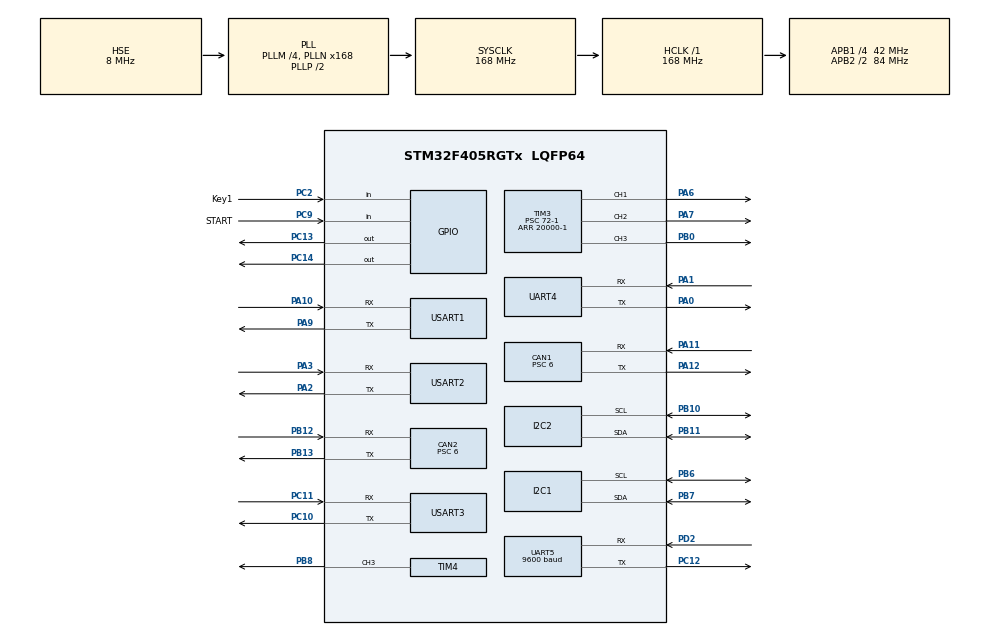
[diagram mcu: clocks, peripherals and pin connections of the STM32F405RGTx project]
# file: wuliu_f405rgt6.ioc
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CAN1.ABOM=ENABLE
CAN1.BS1=CAN_BS1_11TQ
CAN1.BS2=CAN_BS2_2TQ
CAN1.CalculateBaudRate=500000
CAN1.CalculateTimeBit=2000
CAN1.CalculateTimeQuantum=142.85714285714286
CAN1.NART=ENABLE
CAN1.Prescaler=6
CAN2.BS1=CAN_BS1_11TQ
CAN2.BS2=CAN_BS2_2TQ
CAN2.CalculateBaudRate=500000
CAN2.CalculateTimeBit=2000
CAN2.CalculateTimeQuantum=142.85714285714286
CAN2.Prescaler=6
Dma.Request0=USART1_RX
Dma.Request1=USART1_TX
Dma.Request2=USART2_RX
Dma.Request3=USART2_TX
Dma.Request4=UART4_RX
Dma.Request5=UART4_TX
Dma.Request6=USART3_RX
Dma.Request7=USART3_TX
Dma.UART4_RX.4.Direction=DMA_PERIPH_TO_MEMORY
Dma.UART4_RX.4.FIFOMode=DMA_FIFOMODE_DISABLE
Dma.UART4_RX.4.Instance=DMA1_Stream2
Dma.UART4_RX.4.MemDataAlignment=DMA_MDATAALIGN_BYTE
Dma.UART4_RX.4.MemInc=DMA_MINC_ENABLE
Dma.UART4_RX.4.Mode=DMA_CIRCULAR
Dma.UART4_RX.4.PeriphDataAlignment=DMA_PDATAALIGN_BYTE
Dma.UART4_RX.4.PeriphInc=DMA_PINC_DISABLE
Dma.UART4_RX.4.Priority=DMA_PRIORITY_LOW
Dma.UART4_TX.5.Direction=DMA_MEMORY_TO_PERIPH
Dma.UART4_TX.5.FIFOMode=DMA_FIFOMODE_DISABLE
Dma.UART4_TX.5.Instance=DMA1_Stream4
Dma.UART4_TX.5.MemDataAlignment=DMA_MDATAALIGN_BYTE
Dma.UART4_TX.5.MemInc=DMA_MINC_ENABLE
Dma.UART4_TX.5.Mode=DMA_NORMAL
Dma.UART4_TX.5.PeriphDataAlignment=DMA_PDATAALIGN_BYTE
Dma.UART4_TX.5.PeriphInc=DMA_PINC_DISABLE
Dma.UART4_TX.5.Priority=DMA_PRIORITY_LOW
Dma.USART1_RX.0.Direction=DMA_PERIPH_TO_MEMORY
Dma.USART1_RX.0.FIFOMode=DMA_FIFOMODE_DISABLE
Dma.USART1_RX.0.Instance=DMA2_Stream2
Dma.USART1_RX.0.MemDataAlignment=DMA_MDATAALIGN_BYTE
Dma.USART1_RX.0.MemInc=DMA_MINC_ENABLE
Dma.USART1_RX.0.Mode=DMA_NORMAL
Dma.USART1_RX.0.PeriphDataAlignment=DMA_PDATAALIGN_BYTE
Dma.USART1_RX.0.PeriphInc=DMA_PINC_DISABLE
Dma.USART1_RX.0.Priority=DMA_PRIORITY_LOW
Dma.USART1_TX.1.Direction=DMA_MEMORY_TO_PERIPH
Dma.USART1_TX.1.FIFOMode=DMA_FIFOMODE_DISABLE
Dma.USART1_TX.1.Instance=DMA2_Stream7
Dma.USART1_TX.1.MemDataAlignment=DMA_MDATAALIGN_BYTE
Dma.USART1_TX.1.MemInc=DMA_MINC_ENABLE
Dma.USART1_TX.1.Mode=DMA_NORMAL
Dma.USART1_TX.1.PeriphDataAlignment=DMA_PDATAALIGN_BYTE
Dma.USART1_TX.1.PeriphInc=DMA_PINC_DISABLE
Dma.USART1_TX.1.Priority=DMA_PRIORITY_LOW
Dma.USART2_RX.2.Direction=DMA_PERIPH_TO_MEMORY
Dma.USART2_RX.2.FIFOMode=DMA_FIFOMODE_DISABLE
Dma.USART2_RX.2.Instance=DMA1_Stream5
Dma.USART2_RX.2.MemDataAlignment=DMA_MDATAALIGN_BYTE
Dma.USART2_RX.2.MemInc=DMA_MINC_ENABLE
Dma.USART2_RX.2.Mode=DMA_CIRCULAR
Dma.USART2_RX.2.PeriphDataAlignment=DMA_PDATAALIGN_BYTE
Dma.USART2_RX.2.PeriphInc=DMA_PINC_DISABLE
Dma.USART2_RX.2.Priority=DMA_PRIORITY_LOW
Dma.USART2_TX.3.Direction=DMA_MEMORY_TO_PERIPH
Dma.USART2_TX.3.FIFOMode=DMA_FIFOMODE_DISABLE
Dma.USART2_TX.3.Instance=DMA1_Stream6
Dma.USART2_TX.3.MemDataAlignment=DMA_MDATAALIGN_BYTE
Dma.USART2_TX.3.MemInc=DMA_MINC_ENABLE
Dma.USART2_TX.3.Mode=DMA_NORMAL
Dma.USART2_TX.3.PeriphDataAlignment=DMA_PDATAALIGN_BYTE
Dma.USART2_TX.3.PeriphInc=DMA_PINC_DISABLE
Dma.USART2_TX.3.Priority=DMA_PRIORITY_LOW
Dma.USART3_RX.6.Direction=DMA_PERIPH_TO_MEMORY
Dma.USART3_RX.6.FIFOMode=DMA_FIFOMODE_DISABLE
Dma.USART3_RX.6.Instance=DMA1_Stream1
Dma.USART3_RX.6.MemDataAlignment=DMA_MDATAALIGN_BYTE
Dma.USART3_RX.6.MemInc=DMA_MINC_ENABLE
Dma.USART3_RX.6.Mode=DMA_NORMAL
Dma.USART3_RX.6.PeriphDataAlignment=DMA_PDATAALIGN_BYTE
Dma.USART3_RX.6.PeriphInc=DMA_PINC_DISABLE
Dma.USART3_RX.6.Priority=DMA_PRIORITY_LOW
Dma.USART3_TX.7.Direction=DMA_MEMORY_TO_PERIPH
Dma.USART3_TX.7.FIFOMode=DMA_FIFOMODE_DISABLE
Dma.USART3_TX.7.Instance=DMA1_Stream3
Dma.USART3_TX.7.MemDataAlignment=DMA_MDATAALIGN_BYTE
Dma.USART3_TX.7.MemInc=DMA_MINC_ENABLE
Dma.USART3_TX.7.Mode=DMA_NORMAL
Dma.USART3_TX.7.PeriphDataAlignment=DMA_PDATAALIGN_BYTE
Dma.USART3_TX.7.PeriphInc=DMA_PINC_DISABLE
Dma.USART3_TX.7.Priority=DMA_PRIORITY_LOW
FREERTOS.Queues01=KeyQueue,16,uint8_t,0,Dynamic,NULL,NULL;maxicamQueue,16,34,1,Dynamic,NULL,NULL
FREERTOS.Tasks01=defaultTask,8,512,StartDefaultTask,Default,NULL,Dynamic,NULL,NULL;CHASSIS_TASK,25,128,chassis_task,As external,NULL,Dynamic,NULL,NULL;POSITION_TASK,24,128,position_task,As external,NULL,Dynamic,NULL,NULL;MAIN_TASK,16,256,main_task,As external,NULL,Dynamic,NULL,NULL;UART_RX_TASK,18,128,uart_rx_task,As external,NULL,Dynamic,NULL,NULL;MUSIC_TASK,10,128,music_task,As external,NULL,Dynamic,NULL,NULL;KEY_TASK,17,128,key_task,As external,NULL,Dynamic,NULL,NULL;OUTPUT_TASK,11,1024,output_task,As external,NULL,Dynamic,NULL,NULL;RADAR_TASK,19,2048,radar_task,As external,NULL,Dynamic,NULL,NULL;TEST_RADAR_TASK,8,128,test_radar_task,As external,NULL,Dynamic,NULL,NULL
FREERTOS.configTOTAL_HEAP_SIZE=24576
I2C1.I2C_Mode=I2C_Fast
I2C2.I2C_Mode=I2C_Fast
Mcu.Family=STM32F4
Mcu.Name=STM32F405RGTx
Mcu.Package=LQFP64
NVIC.CAN1_RX0_IRQn=true\:5\:0\:false\:false\:true\:true\:true\:true\:true
NVIC.CAN2_RX0_IRQn=true\:5\:0\:false\:false\:true\:true\:true\:true\:true
NVIC.DMA1_Stream1_IRQn=true\:5\:0\:false\:false\:true\:true\:false\:true\:true
NVIC.DMA1_Stream2_IRQn=true\:5\:0\:false\:false\:true\:true\:false\:true\:true
NVIC.DMA1_Stream3_IRQn=true\:5\:0\:false\:false\:true\:true\:false\:true\:true
NVIC.DMA1_Stream4_IRQn=true\:5\:0\:false\:false\:true\:true\:false\:true\:true
NVIC.DMA1_Stream5_IRQn=true\:5\:0\:false\:false\:true\:true\:false\:true\:true
NVIC.DMA1_Stream6_IRQn=true\:5\:0\:false\:false\:true\:true\:false\:true\:true
NVIC.DMA2_Stream2_IRQn=true\:5\:0\:false\:false\:true\:true\:false\:true\:true
NVIC.DMA2_Stream7_IRQn=true\:5\:0\:false\:false\:true\:true\:false\:true\:true
NVIC.PriorityGroup=NVIC_PRIORITYGROUP_4
NVIC.TIM6_DAC_IRQn=true\:15\:0\:false\:false\:true\:false\:false\:true\:true
NVIC.TimeBase=TIM6_DAC_IRQn
NVIC.TimeBaseIP=TIM6
NVIC.UART4_IRQn=true\:5\:0\:false\:false\:true\:true\:true\:true\:true
NVIC.UART5_IRQn=true\:5\:0\:false\:false\:true\:true\:true\:true\:true
NVIC.USART1_IRQn=true\:5\:0\:false\:false\:true\:true\:true\:true\:true
NVIC.USART2_IRQn=true\:5\:0\:false\:false\:true\:true\:true\:true\:true
NVIC.USART3_IRQn=true\:5\:0\:false\:false\:true\:true\:true\:true\:true
PA0-WKUP.Mode=Asynchronous
PA0-WKUP.Signal=UART4_TX
PA1.Mode=Asynchronous
PA1.Signal=UART4_RX
PA10.Mode=Asynchronous
PA10.Signal=USART1_RX
PA11.Mode=CAN_Activate
PA11.Signal=CAN1_RX
PA12.Mode=CAN_Activate
PA12.Signal=CAN1_TX
PA13.Mode=Serial_Wire
PA13.Signal=SYS_JTMS-SWDIO
PA14.Mode=Serial_Wire
PA14.Signal=SYS_JTCK-SWCLK
PA2.Mode=Asynchronous
PA2.Signal=USART2_TX
PA3.Mode=Asynchronous
PA3.Signal=USART2_RX
PA6.Signal=S_TIM3_CH1
PA7.Signal=S_TIM3_CH2
PA9.Mode=Asynchronous
PA9.Signal=USART1_TX
PB0.Signal=S_TIM3_CH3
PB10.Mode=I2C
PB10.Signal=I2C2_SCL
PB11.Mode=I2C
PB11.Signal=I2C2_SDA
PB12.Mode=CAN_Activate
PB12.Signal=CAN2_RX
PB13.Mode=CAN_Activate
PB13.Signal=CAN2_TX
PB6.Mode=I2C
PB6.Signal=I2C1_SCL
PB7.Mode=I2C
PB7.Signal=I2C1_SDA
PB8.Signal=S_TIM4_CH3
PC10.Mode=Asynchronous
PC10.Signal=USART3_TX
PC11.Mode=Asynchronous
PC11.Signal=USART3_RX
PC12.Mode=Asynchronous
PC12.Signal=UART5_TX
PC13-ANTI_TAMP.Signal=GPIO_Output
PC14-OSC32_IN.Signal=GPIO_Output
PC2.GPIO_Label=Key1
PC2.Signal=GPIO_Input
PC9.GPIO_Label=START
PC9.GPIO_PuPd=GPIO_PULLUP
PC9.Signal=GPIO_Input
PD2.Mode=Asynchronous
PD2.Signal=UART5_RX
PH0-OSC_IN.Mode=HSE-External-Oscillator
PH0-OSC_IN.Signal=RCC_OSC_IN
PH1-OSC_OUT.Mode=HSE-External-Oscillator
PH1-OSC_OUT.Signal=RCC_OSC_OUT
ProjectManager.HeapSize=0x200
ProjectManager.StackSize=0x400
ProjectManager.TargetToolchain=CMake
RCC.48MHZClocksFreq_Value=84000000
RCC.AHBFreq_Value=168000000
RCC.APB1CLKDivider=RCC_HCLK_DIV4
RCC.APB1Freq_Value=42000000
RCC.APB1TimFreq_Value=84000000
RCC.APB2CLKDivider=RCC_HCLK_DIV2
RCC.APB2Freq_Value=84000000
RCC.APB2TimFreq_Value=168000000
RCC.CortexFreq_Value=168000000
RCC.HCLKFreq_Value=168000000
RCC.HSE_VALUE=8000000
RCC.HSI_VALUE=16000000
RCC.LSE_VALUE=32768
RCC.PLLM=4
RCC.PLLN=168
RCC.PLLSourceVirtual=RCC_PLLSOURCE_HSE
RCC.SYSCLKFreq_VALUE=168000000
RCC.SYSCLKSource=RCC_SYSCLKSOURCE_PLLCLK
RCC.VCOOutputFreq_Value=336000000
SH.S_TIM3_CH1.0=TIM3_CH1,PWM Generation1 CH1
SH.S_TIM3_CH2.0=TIM3_CH2,PWM Generation2 CH2
SH.S_TIM3_CH3.0=TIM3_CH3,PWM Generation3 CH3
SH.S_TIM4_CH3.0=TIM4_CH3,PWM Generation3 CH3
STMicroelectronics.X-CUBE-ALGOBUILD.1.4.0.LibraryCcDSPOoLibraryJjDSPOoLibrary=true
TIM3.Channel-PWM\ Generation1\ CH1=TIM_CHANNEL_1
TIM3.Channel-PWM\ Generation2\ CH2=TIM_CHANNEL_2
TIM3.Channel-PWM\ Generation3\ CH3=TIM_CHANNEL_3
TIM3.Period=20000-1
TIM3.Prescaler=72-1
TIM4.Channel-PWM\ Generation3\ CH3=TIM_CHANNEL_3
TIM4.Period=1000-1
TIM4.Prescaler=72-1
UART4.VirtualMode=Asynchronous
UART5.BaudRate=9600
UART5.VirtualMode=Asynchronous
USART1.VirtualMode=VM_ASYNC
USART2.VirtualMode=VM_ASYNC
USART3.VirtualMode=VM_ASYNC
VP_FREERTOS_VS_CMSIS_V2.Mode=CMSIS_V2
VP_STMicroelectronics.X-CUBE-ALGOBUILD_VS_DSPOoLibraryJjLibrary_1.4.0_1.4.0.Mode=DSPOoLibraryJjLibrary
VP_SYS_VS_tim6.Mode=TIM6
VP_TIM3_VS_ClockSourceINT.Mode=Internal
VP_TIM4_VS_ClockSourceINT.Mode=Internal
board=custom

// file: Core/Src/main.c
/* USER CODE BEGIN Header */
/**
  ******************************************************************************
  * @file           : main.c
  * @brief          : Main program body
  ******************************************************************************
  * @attention
  *
  * Copyright (c) 2026 STMicroelectronics.
  * All rights reserved.
  *
  * This software is licensed under terms that can be found in the LICENSE file
  * in the root directory of this software component.
  * If no LICENSE file comes with this software, it is provided AS-IS.
  *
  ******************************************************************************
  */
/* USER CODE END Header */
#include "main.h"
#include "cmsis_os.h"
#include "can.h"
#include "dma.h"
#include "i2c.h"
#include "tim.h"
#include "usart.h"
#include "gpio.h"

/* USER CODE BEGIN Includes */
#include "bsp_buzzer_pwm.h"
#include "bsp_can.h"
#include "bsp_servo_pwm.h"
#include "OLED.h"
#include "radar_task.h"

/* USER CODE END Includes */

void SystemClock_Config(void);
void MX_FREERTOS_Init(void);

int main(void)
{

  /* MCU Configuration--------------------------------------------------------*/

  /* Reset of all peripherals, Initializes the Flash interface and the Systick. */
  HAL_Init();

  /* Configure the system clock */
  SystemClock_Config();

  /* Initialize all configured peripherals */
  MX_GPIO_Init();
  MX_DMA_Init();
  MX_CAN1_Init();
  MX_CAN2_Init();
  MX_I2C1_Init();
  MX_UART4_Init();
  MX_UART5_Init();
  MX_USART1_UART_Init();
  MX_USART2_UART_Init();
  MX_TIM3_Init();
  MX_I2C2_Init();
  MX_TIM4_Init();
  MX_USART3_UART_Init();
  /* USER CODE BEGIN 2 */
  buzzer_init(); // 初始化蜂鸣器
  can_filter_init(); // 初始化CAN接收
  bsp_servo_pwm_init(); // 初始化云台和夹爪舵机PWM
  OLED_Init(); // 初始化OLED显示屏
  RadarBridge_CreateQueues();
  // DWT_Delay_Init(); // 初始化DWT延时函数

  /* USER CODE END 2 */

  /* Init scheduler */
  osKernelInitialize();  /* Call init function for freertos objects (in cmsis_os2.c) */
  MX_FREERTOS_Init();

  /* Start scheduler */
  osKernelStart();

  /* We should never get here as control is now taken by the scheduler */

  /* Infinite loop */
  while (1)
  {

  }
}

void SystemClock_Config(void)
{
  RCC_OscInitTypeDef RCC_OscInitStruct = {0};
  RCC_ClkInitTypeDef RCC_ClkInitStruct = {0};

  /** Configure the main internal regulator output voltage
  */
  __HAL_RCC_PWR_CLK_ENABLE();
  __HAL_PWR_VOLTAGESCALING_CONFIG(PWR_REGULATOR_VOLTAGE_SCALE1);

  /** Initializes the RCC Oscillators according to the specified parameters
  * in the RCC_OscInitTypeDef structure.
  */
  RCC_OscInitStruct.OscillatorType = RCC_OSCILLATORTYPE_HSE;
  RCC_OscInitStruct.HSEState = RCC_HSE_ON;
  RCC_OscInitStruct.PLL.PLLState = RCC_PLL_ON;
  RCC_OscInitStruct.PLL.PLLSource = RCC_PLLSOURCE_HSE;
  RCC_OscInitStruct.PLL.PLLM = 4;
  RCC_OscInitStruct.PLL.PLLN = 168;
  RCC_OscInitStruct.PLL.PLLP = RCC_PLLP_DIV2;
  RCC_OscInitStruct.PLL.PLLQ = 4;
  if (HAL_RCC_OscConfig(&RCC_OscInitStruct) != HAL_OK)
  {
    Error_Handler();
  }

  /** Initializes the CPU, AHB and APB buses clocks
  */
  RCC_ClkInitStruct.ClockType = RCC_CLOCKTYPE_HCLK|RCC_CLOCKTYPE_SYSCLK
                              |RCC_CLOCKTYPE_PCLK1|RCC_CLOCKTYPE_PCLK2;
  RCC_ClkInitStruct.SYSCLKSource = RCC_SYSCLKSOURCE_PLLCLK;
  RCC_ClkInitStruct.AHBCLKDivider = RCC_SYSCLK_DIV1;
  RCC_ClkInitStruct.APB1CLKDivider = RCC_HCLK_DIV4;
  RCC_ClkInitStruct.APB2CLKDivider = RCC_HCLK_DIV2;

  if (HAL_RCC_ClockConfig(&RCC_ClkInitStruct, FLASH_LATENCY_5) != HAL_OK)
  {
    Error_Handler();
  }
}

void HAL_TIM_PeriodElapsedCallback(TIM_HandleTypeDef *htim)
{
  if (htim->Instance == TIM6)
  {
    HAL_IncTick();
  }
}

void Error_Handler(void)
{
  __disable_irq();
  while (1)
  {
  }
}

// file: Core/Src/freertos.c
/* USER CODE BEGIN Header */
/**
  ******************************************************************************
  * File Name          : freertos.c
  * Description        : Code for freertos applications
  ******************************************************************************
  * @attention
  *
  * Copyright (c) 2026 STMicroelectronics.
  * All rights reserved.
  *
  * This software is licensed under terms that can be found in the LICENSE file
  * in the root directory of this software component.
  * If no LICENSE file comes with this software, it is provided AS-IS.
  *
  ******************************************************************************
  */
/* USER CODE END Header */

#include "FreeRTOS.h"
#include "task.h"
#include "main.h"
#include "cmsis_os.h"

/* Definitions for defaultTask */
osThreadId_t defaultTaskHandle;
const osThreadAttr_t defaultTask_attributes = {
  .name = "defaultTask",
  .stack_size = 512 * 4,
  .priority = (osPriority_t) osPriorityLow,
};
/* Definitions for CHASSIS_TASK */
osThreadId_t CHASSIS_TASKHandle;
const osThreadAttr_t CHASSIS_TASK_attributes = {
  .name = "CHASSIS_TASK",
  .stack_size = 128 * 4,
  .priority = (osPriority_t) osPriorityNormal1,
};
/* Definitions for POSITION_TASK */
osThreadId_t POSITION_TASKHandle;
const osThreadAttr_t POSITION_TASK_attributes = {
  .name = "POSITION_TASK",
  .stack_size = 128 * 4,
  .priority = (osPriority_t) osPriorityNormal,
};
/* Definitions for MAIN_TASK */
osThreadId_t MAIN_TASKHandle;
const osThreadAttr_t MAIN_TASK_attributes = {
  .name = "MAIN_TASK",
  .stack_size = 256 * 4,
  .priority = (osPriority_t) osPriorityBelowNormal,
};
/* Definitions for UART_RX_TASK */
osThreadId_t UART_RX_TASKHandle;
const osThreadAttr_t UART_RX_TASK_attributes = {
  .name = "UART_RX_TASK",
  .stack_size = 128 * 4,
  .priority = (osPriority_t) osPriorityBelowNormal2,
};
/* Definitions for MUSIC_TASK */
osThreadId_t MUSIC_TASKHandle;
const osThreadAttr_t MUSIC_TASK_attributes = {
  .name = "MUSIC_TASK",
  .stack_size = 128 * 4,
  .priority = (osPriority_t) osPriorityLow2,
};
/* Definitions for KEY_TASK */
osThreadId_t KEY_TASKHandle;
const osThreadAttr_t KEY_TASK_attributes = {
  .name = "KEY_TASK",
  .stack_size = 128 * 4,
  .priority = (osPriority_t) osPriorityBelowNormal1,
};
/* Definitions for OUTPUT_TASK */
osThreadId_t OUTPUT_TASKHandle;
const osThreadAttr_t OUTPUT_TASK_attributes = {
  .name = "OUTPUT_TASK",
  .stack_size = 1024 * 4,
  .priority = (osPriority_t) osPriorityLow3,
};
/* Definitions for RADAR_TASK */
osThreadId_t RADAR_TASKHandle;
const osThreadAttr_t RADAR_TASK_attributes = {
  .name = "RADAR_TASK",
  .stack_size = 2048 * 4,
  .priority = (osPriority_t) osPriorityBelowNormal3,
};
/* Definitions for TEST_RADAR_TASK */
osThreadId_t TEST_RADAR_TASKHandle;
const osThreadAttr_t TEST_RADAR_TASK_attributes = {
  .name = "TEST_RADAR_TASK",
  .stack_size = 128 * 4,
  .priority = (osPriority_t) osPriorityLow,
};
/* Definitions for KeyQueue */
osMessageQueueId_t KeyQueueHandle;
const osMessageQueueAttr_t KeyQueue_attributes = {
  .name = "KeyQueue"
};
/* Definitions for maxicamQueue */
osMessageQueueId_t maxicamQueueHandle;
const osMessageQueueAttr_t maxicamQueue_attributes = {
  .name = "maxicamQueue"
};

void StartDefaultTask(void *argument);
extern void chassis_task(void *argument);
extern void position_task(void *argument);
extern void main_task(void *argument);
extern void uart_rx_task(void *argument);
extern void music_task(void *argument);
extern void key_task(void *argument);
extern void output_task(void *argument);
extern void radar_task(void *argument);
extern void test_radar_task(void *argument);

void MX_FREERTOS_Init(void); /* (MISRA C 2004 rule 8.1) */

void MX_FREERTOS_Init(void) {

  /* Create the queue(s) */
  /* creation of KeyQueue */
  KeyQueueHandle = osMessageQueueNew (16, sizeof(uint8_t), &KeyQueue_attributes);

  /* creation of maxicamQueue */
  maxicamQueueHandle = osMessageQueueNew (16, 34, &maxicamQueue_attributes);

  /* Create the thread(s) */
  /* creation of defaultTask */
  defaultTaskHandle = osThreadNew(StartDefaultTask, NULL, &defaultTask_attributes);

  /* creation of CHASSIS_TASK */
  CHASSIS_TASKHandle = osThreadNew(chassis_task, NULL, &CHASSIS_TASK_attributes);

  /* creation of POSITION_TASK */
  POSITION_TASKHandle = osThreadNew(position_task, NULL, &POSITION_TASK_attributes);

  /* creation of MAIN_TASK */
  MAIN_TASKHandle = osThreadNew(main_task, NULL, &MAIN_TASK_attributes);

  /* creation of UART_RX_TASK */
  UART_RX_TASKHandle = osThreadNew(uart_rx_task, NULL, &UART_RX_TASK_attributes);

  /* creation of MUSIC_TASK */
  MUSIC_TASKHandle = osThreadNew(music_task, NULL, &MUSIC_TASK_attributes);

  /* creation of KEY_TASK */
  KEY_TASKHandle = osThreadNew(key_task, NULL, &KEY_TASK_attributes);

  /* creation of OUTPUT_TASK */
  OUTPUT_TASKHandle = osThreadNew(output_task, NULL, &OUTPUT_TASK_attributes);

  /* creation of RADAR_TASK */
  RADAR_TASKHandle = osThreadNew(radar_task, NULL, &RADAR_TASK_attributes);

  /* creation of TEST_RADAR_TASK */
  TEST_RADAR_TASKHandle = osThreadNew(test_radar_task, NULL, &TEST_RADAR_TASK_attributes);

}

void StartDefaultTask(void *argument)
{
  for(;;)
  {
    osDelay(1);
  }
}
